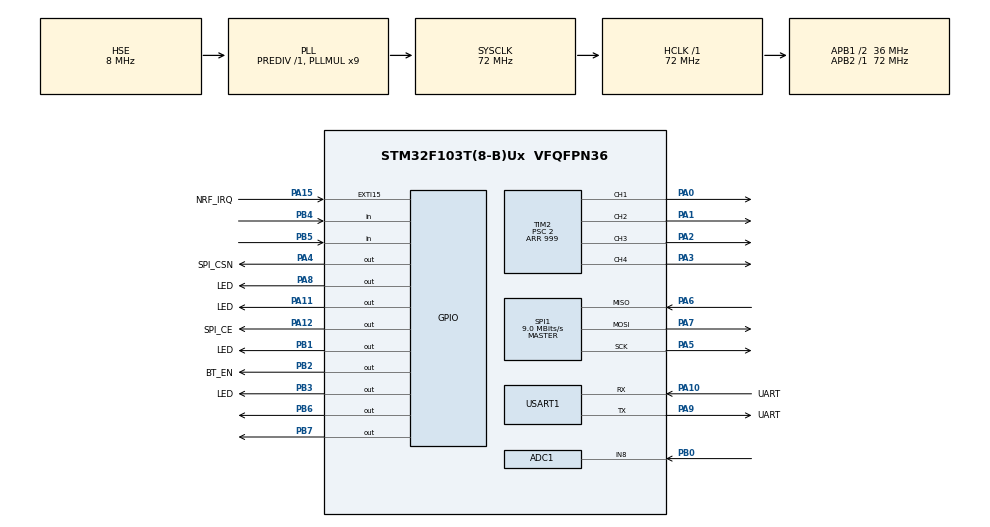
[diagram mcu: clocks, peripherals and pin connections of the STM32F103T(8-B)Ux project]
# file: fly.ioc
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ADC1.AutoInjectedConv=DISABLE
ADC1.Channel-6\#ChannelRegularConversion=ADC_CHANNEL_TEMPSENSOR
ADC1.Channel-7\#ChannelRegularConversion=ADC_CHANNEL_8
ADC1.ContinuousConvMode=DISABLE
ADC1.ExternalTrigConv=ADC_SOFTWARE_START
ADC1.InjNumberOfConversion=0
ADC1.InjectedDiscontinuousConvMode=DISABLE
ADC1.NbrOfConversion=2
ADC1.NbrOfConversionFlag=1
ADC1.Rank-6\#ChannelRegularConversion=1
ADC1.Rank-7\#ChannelRegularConversion=2
ADC1.SamplingTime-6\#ChannelRegularConversion=ADC_SAMPLETIME_239CYCLES_5
ADC1.SamplingTime-7\#ChannelRegularConversion=ADC_SAMPLETIME_239CYCLES_5
ADC1.master=1
Mcu.Family=STM32F1
Mcu.Name=STM32F103T(8-B)Ux
Mcu.Package=VFQFPN36
NVIC.PriorityGroup=NVIC_PRIORITYGROUP_2
NVIC.TIM3_IRQn=true\:2\:0\:true\:true\:true\:3
NVIC.TIM4_IRQn=true\:1\:1\:true\:true\:true\:2
NVIC.USART1_IRQn=true\:0\:1\:true\:true\:true\:1
PA0-WKUP.Signal=S_TIM2_CH1_ETR
PA1.Signal=S_TIM2_CH2
PA10.GPIO_Label=UART
PA10.Mode=Asynchronous
PA10.Signal=USART1_RX
PA11.GPIO_Label=LED
PA11.Signal=GPIO_Output
PA12.GPIO_Label=SPI_CE
PA12.GPIO_Speed=GPIO_SPEED_FREQ_MEDIUM
PA12.PinState=GPIO_PIN_RESET
PA12.Signal=GPIO_Output
PA13.Mode=Serial_Wire
PA13.Signal=SYS_JTMS-SWDIO
PA14.Mode=Serial_Wire
PA14.Signal=SYS_JTCK-SWCLK
PA15.GPIO_Label=NRF_IRQ
PA15.Signal=GPXTI15
PA2.Signal=S_TIM2_CH3
PA3.Signal=S_TIM2_CH4
PA4.GPIO_Label=SPI_CSN
PA4.GPIO_Speed=GPIO_SPEED_FREQ_MEDIUM
PA4.PinState=GPIO_PIN_SET
PA4.Signal=GPIO_Output
PA5.GPIO_Speed=GPIO_SPEED_FREQ_MEDIUM
PA5.Mode=Full_Duplex_Master
PA5.Signal=SPI1_SCK
PA6.Mode=Full_Duplex_Master
PA6.Signal=SPI1_MISO
PA7.GPIO_Speed=GPIO_SPEED_FREQ_MEDIUM
PA7.Mode=Full_Duplex_Master
PA7.Signal=SPI1_MOSI
PA8.GPIO_Label=LED
PA8.Signal=GPIO_Output
PA9.GPIO_Label=UART
PA9.GPIO_Speed=GPIO_SPEED_FREQ_MEDIUM
PA9.Mode=Asynchronous
PA9.Signal=USART1_TX
PB0.Signal=ADCx_IN8
PB1.GPIO_Label=LED
PB1.Signal=GPIO_Output
PB2.GPIO_Label=BT_EN
PB2.Signal=GPIO_Output
PB3.GPIO_Label=LED
PB3.Signal=GPIO_Output
PB4.Signal=GPIO_Input
PB5.Signal=GPIO_Input
PB6.Signal=GPIO_Output
PB7.Signal=GPIO_Output
PD0-OSC_IN.Mode=HSE-External-Oscillator
PD0-OSC_IN.Signal=RCC_OSC_IN
PD1-OSC_OUT.Mode=HSE-External-Oscillator
PD1-OSC_OUT.Signal=RCC_OSC_OUT
ProjectManager.HeapSize=0x400
ProjectManager.StackSize=0x200
ProjectManager.TargetToolchain=MDK-ARM V5
RCC.ADCPresc=RCC_ADCPCLK2_DIV6
RCC.AHBFreq_Value=72000000
RCC.APB1CLKDivider=RCC_HCLK_DIV2
RCC.APB1Freq_Value=36000000
RCC.APB1TimFreq_Value=72000000
RCC.APB2Freq_Value=72000000
RCC.APB2TimFreq_Value=72000000
RCC.ClockTypeHCLK=RCC_CLOCKTYPE_HCLK
RCC.ClockTypePCLK1=RCC_CLOCKTYPE_PCLK1
RCC.ClockTypePCLK2=RCC_CLOCKTYPE_PCLK2
RCC.EnableHSE=true
RCC.EnableHSERTCDevisor=false
RCC.EnableLSE=false
RCC.EnableLSERTC=false
RCC.EnableMCOMultDivisor=false
RCC.HCLKFreq_Value=72000000
RCC.HSEState=RCC_HSE_ON
RCC.HSIState=RCC_HSI_ON
RCC.IWDGEnable=false
RCC.LSIState=RCC_LSI_OFF
RCC.MCOEnable=false
RCC.OscillatorTypeHSE=RCC_OSCILLATORTYPE_HSE
RCC.PLLMUL=RCC_PLL_MUL9
RCC.PLLSource=RCC_PLLSOURCE_HSE
RCC.PLLSourceVirtual=RCC_PLLSOURCE_HSE
RCC.PLLState=RCC_PLL_ON
RCC.RTCEnable=false
RCC.SYSCLKFreq_VALUE=72000000
RCC.SYSCLKSource=RCC_SYSCLKSOURCE_PLLCLK
RCC.USBFreq_Value=72000000
SH.ADCx_IN8.0=ADC1_IN8,IN8
SH.S_TIM2_CH1_ETR.0=TIM2_CH1,PWM Generation1 CH1
SH.S_TIM2_CH2.0=TIM2_CH2,PWM Generation2 CH2
SH.S_TIM2_CH3.0=TIM2_CH3,PWM Generation3 CH3
SH.S_TIM2_CH4.0=TIM2_CH4,PWM Generation4 CH4
SPI1.BaudRatePrescaler=SPI_BAUDRATEPRESCALER_8
SPI1.CRCCalculation=SPI_CRCCALCULATION_DISABLE
SPI1.CRCPolynomial=10
SPI1.CalculateBaudRate=9.0 MBits/s
SPI1.Direction=SPI_DIRECTION_2LINES
SPI1.Mode=SPI_MODE_MASTER
SPI1.VirtualType=VM_MASTER
TIM2.Channel-PWM\ Generation1\ CH1=TIM_CHANNEL_1
TIM2.Channel-PWM\ Generation2\ CH2=TIM_CHANNEL_2
TIM2.Channel-PWM\ Generation3\ CH3=TIM_CHANNEL_3
TIM2.Channel-PWM\ Generation4\ CH4=TIM_CHANNEL_4
TIM2.Period=999
TIM2.Prescaler=2
TIM3.Period=1999
TIM3.Prescaler=71
TIM4.Period=999
TIM4.Prescaler=71
USART1.HwFlowCtl-Asynchronous=UART_HWCONTROL_NONE
USART1.VirtualMode=VM_ASYNC
VP_ADC1_TempSens_Input.Mode=IN-TempSens
VP_TIM2_VS_ClockSourceINT.Mode=Internal
VP_TIM3_VS_ClockSourceINT.Mode=Internal
VP_TIM4_VS_ClockSourceINT.Mode=Internal
board=fly

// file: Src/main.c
/**
  ******************************************************************************
  * File Name          : main.c
  * Description        : Main program body
  ******************************************************************************
  *
  * COPYRIGHT(c) 2017 STMicroelectronics
  *
  * Redistribution and use in source and binary forms, with or without modification,
  * are permitted provided that the following conditions are met:
  *   1. Redistributions of source code must retain the above copyright notice,
  *      this list of conditions and the following disclaimer.
  *   2. Redistributions in binary form must reproduce the above copyright notice,
  *      this list of conditions and the following disclaimer in the documentation
  *      and/or other materials provided with the distribution.
  *   3. Neither the name of STMicroelectronics nor the names of its contributors
  *      may be used to endorse or promote products derived from this software
  *      without specific prior written permission.
  *
  * THIS SOFTWARE IS PROVIDED BY THE COPYRIGHT HOLDERS AND CONTRIBUTORS "AS IS"
  * AND ANY EXPRESS OR IMPLIED WARRANTIES, INCLUDING, BUT NOT LIMITED TO, THE
  * IMPLIED WARRANTIES OF MERCHANTABILITY AND FITNESS FOR A PARTICULAR PURPOSE ARE
  * DISCLAIMED. IN NO EVENT SHALL THE COPYRIGHT HOLDER OR CONTRIBUTORS BE LIABLE
  * FOR ANY DIRECT, INDIRECT, INCIDENTAL, SPECIAL, EXEMPLARY, OR CONSEQUENTIAL
  * DAMAGES (INCLUDING, BUT NOT LIMITED TO, PROCUREMENT OF SUBSTITUTE GOODS OR
  * SERVICES; LOSS OF USE, DATA, OR PROFITS; OR BUSINESS INTERRUPTION) HOWEVER
  * CAUSED AND ON ANY THEORY OF LIABILITY, WHETHER IN CONTRACT, STRICT LIABILITY,
  * OR TORT (INCLUDING NEGLIGENCE OR OTHERWISE) ARISING IN ANY WAY OUT OF THE USE
  * OF THIS SOFTWARE, EVEN IF ADVISED OF THE POSSIBILITY OF SUCH DAMAGE.
  *
  ******************************************************************************
  */
#include "main.h"
#include "stm32f1xx_hal.h"
#include "adc.h"
#include "spi.h"
#include "tim.h"
#include "usart.h"
#include "gpio.h"

/* USER CODE BEGIN PV */
/* Private variables ---------------------------------------------------------*/

/* USER CODE END PV */

void SystemClock_Config(void);
void Error_Handler(void);
static void MX_NVIC_Init(void);

/* USER CODE BEGIN PFP */
/* Private function prototypes -----------------------------------------------*/

/* USER CODE END PFP */

int main(void)
{

  /* MCU Configuration----------------------------------------------------------*/

  /* Reset of all peripherals, Initializes the Flash interface and the Systick. */
  HAL_Init();

  /* Configure the system clock */
  SystemClock_Config();

  /* Initialize all configured peripherals */
  MX_GPIO_Init();
  MX_ADC1_Init();
  MX_SPI1_Init();
  MX_USART1_UART_Init();
  MX_TIM2_Init();
  MX_TIM3_Init();
  MX_TIM4_Init();

  /* Initialize interrupts */
  MX_NVIC_Init();

  /* USER CODE BEGIN 2 */
	Motor_Start();
	MotorPwmFlash(400,400,400,400);

//	printf("the SystemCoreClock is : %d\n\r",SystemCoreClock);
//	printf("the HAL_RCC_GetPCLK1Freq is : %d\n\r",HAL_RCC_GetPCLK1Freq());
//  printf("the USART1 BaudRate is : %d\n\r",115200);
  /* USER CODE END 2 */

  /* Infinite loop */
  while (1)
  {

  /* USER CODE BEGIN 3 */
	  printf("the SystemCoreClock is : %d\n\r",SystemCoreClock);
	  printf("the HAL_RCC_GetPCLK1Freq is : %d\n\r",HAL_RCC_GetPCLK1Freq());
    printf("the USART1 BaudRate is : %d\n\r",115200);

		HAL_Delay(5000);

  }
  /* USER CODE END 3 */

}

/** System Clock Configuration
*/
void SystemClock_Config(void)
{

  RCC_OscInitTypeDef RCC_OscInitStruct;
  RCC_ClkInitTypeDef RCC_ClkInitStruct;
  RCC_PeriphCLKInitTypeDef PeriphClkInit;

    /**Initializes the CPU, AHB and APB busses clocks
    */
  RCC_OscInitStruct.OscillatorType = RCC_OSCILLATORTYPE_HSE;
  RCC_OscInitStruct.HSEState = RCC_HSE_ON;
  RCC_OscInitStruct.HSEPredivValue = RCC_HSE_PREDIV_DIV1;
  RCC_OscInitStruct.HSIState = RCC_HSI_ON;
  RCC_OscInitStruct.PLL.PLLState = RCC_PLL_ON;
  RCC_OscInitStruct.PLL.PLLSource = RCC_PLLSOURCE_HSE;
  RCC_OscInitStruct.PLL.PLLMUL = RCC_PLL_MUL9;
  if (HAL_RCC_OscConfig(&RCC_OscInitStruct) != HAL_OK)
  {
    Error_Handler();
  }

    /**Initializes the CPU, AHB and APB busses clocks
    */
  RCC_ClkInitStruct.ClockType = RCC_CLOCKTYPE_HCLK|RCC_CLOCKTYPE_SYSCLK
                              |RCC_CLOCKTYPE_PCLK1|RCC_CLOCKTYPE_PCLK2;
  RCC_ClkInitStruct.SYSCLKSource = RCC_SYSCLKSOURCE_PLLCLK;
  RCC_ClkInitStruct.AHBCLKDivider = RCC_SYSCLK_DIV1;
  RCC_ClkInitStruct.APB1CLKDivider = RCC_HCLK_DIV2;
  RCC_ClkInitStruct.APB2CLKDivider = RCC_HCLK_DIV1;

  if (HAL_RCC_ClockConfig(&RCC_ClkInitStruct, FLASH_LATENCY_2) != HAL_OK)
  {
    Error_Handler();
  }

  PeriphClkInit.PeriphClockSelection = RCC_PERIPHCLK_ADC;
  PeriphClkInit.AdcClockSelection = RCC_ADCPCLK2_DIV6;
  if (HAL_RCCEx_PeriphCLKConfig(&PeriphClkInit) != HAL_OK)
  {
    Error_Handler();
  }

    /**Configure the Systick interrupt time
    */
  HAL_SYSTICK_Config(HAL_RCC_GetHCLKFreq()/1000);

    /**Configure the Systick
    */
  HAL_SYSTICK_CLKSourceConfig(SYSTICK_CLKSOURCE_HCLK);

  /* SysTick_IRQn interrupt configuration */
  HAL_NVIC_SetPriority(SysTick_IRQn, 0, 0);
}

/** NVIC Configuration
*/
static void MX_NVIC_Init(void)
{
  /* USART1_IRQn interrupt configuration */
  HAL_NVIC_SetPriority(USART1_IRQn, 0, 1);
  HAL_NVIC_EnableIRQ(USART1_IRQn);
  /* TIM4_IRQn interrupt configuration */
  HAL_NVIC_SetPriority(TIM4_IRQn, 1, 1);
  HAL_NVIC_EnableIRQ(TIM4_IRQn);
  /* TIM3_IRQn interrupt configuration */
  HAL_NVIC_SetPriority(TIM3_IRQn, 2, 0);
  HAL_NVIC_EnableIRQ(TIM3_IRQn);
}

void Error_Handler(void)
{
  while(1)
  {
  }
}

/************************ (C) COPYRIGHT STMicroelectronics *****END OF FILE****/
